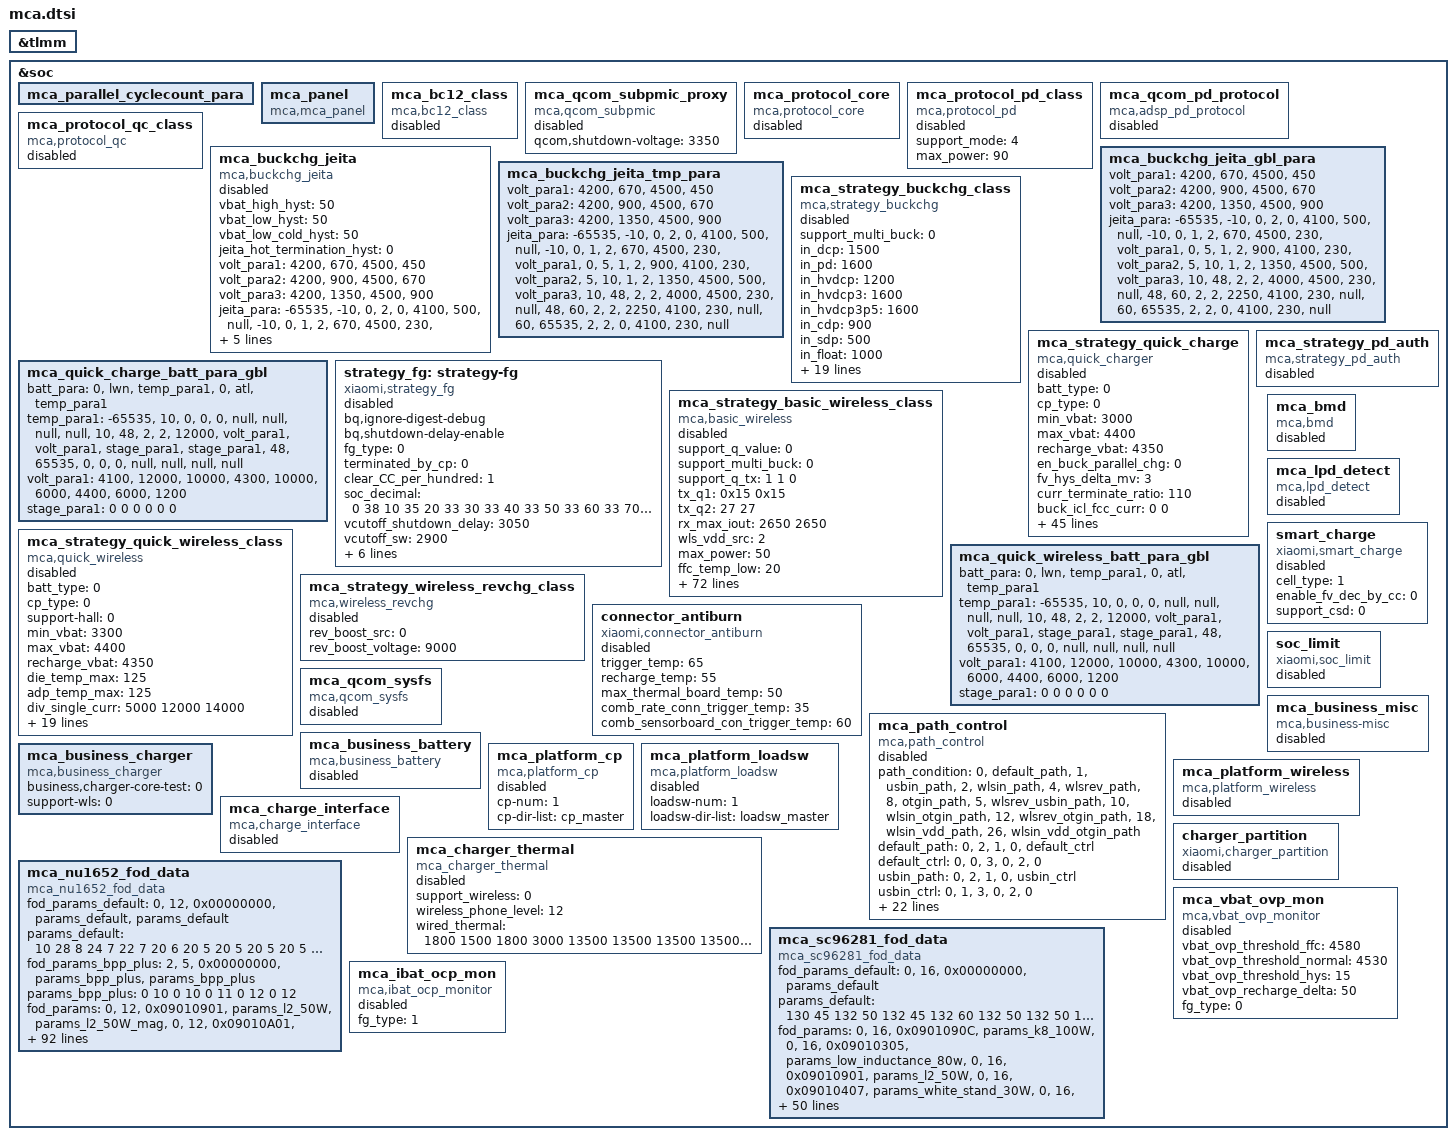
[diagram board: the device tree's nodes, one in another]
&tlmm {
};

&soc {
	mca_parallel_cyclecount_para: mca_parallel_cyclecount_para {
	};

	mca_panel: mca_panel {
		compatible = "mca,mca_panel";
		status = "ok";
	};

	mca_bc12_class: mca_bc12_class {
		compatible = "mca,bc12_class";
		status = "disabled";
	};

	mca_qcom_subpmic_proxy: mca_qcom_subpmic_proxy {
		compatible = "mca,qcom_subpmic";
		qcom,shutdown-voltage = <3350>;
		status = "disabled";
	};

	mca_protocol_core: mca_protocol_core {
		compatible = "mca,protocol_core";
		status = "disabled";
	};

	mca_protocol_pd_class: mca_protocol_pd_class {
		compatible = "mca,protocol_pd";
		status = "disabled";
		support_mode = <4>;
		max_power = <90>;
	};

	mca_qcom_pd_protocol: mca_qcom_pd_protocol {
		compatible = "mca,adsp_pd_protocol";
		status = "disabled";
	};

	mca_protocol_qc_class: mca_protocol_qc_class {
		compatible = "mca,protocol_qc";
		status = "disabled";
	};

	mca_buckchg_jeita: mca_buckchg_jeita {
		compatible = "mca,buckchg_jeita";
		vbat_high_hyst = <50>;
		vbat_low_hyst = <50>;
		vbat_low_cold_hyst = <50>;
		jeita_hot_termination_hyst = <0>;
		volt_para1 =
			"4200", "670",
			"4500", "450";
		volt_para2 =
			"4200", "900",
			"4500", "670";
		volt_para3 =
			"4200", "1350",
			"4500", "900";
		/* temp_low, temp_high, low_temp_hys, high_temp_hys, max_current, vterm, iterm volt_para_name */
		jeita_para =
			"-65535", "-10", "0", "2", "0", "4100", "500", "null",
			"-10", "0", "1", "2", "670", "4500", "230", "volt_para1",
			"0", "5", "1", "2", "900", "4100", "230", "volt_para2",
			"5", "10", "1", "2", "1350", "4500", "500", "volt_para3",
			"10", "48", "2", "2", "4000", "4500", "230", "null",
			"48", "60", "2", "2", "2250", "4100", "230", "null" ,
			"60", "65535", "2", "2", "0", "4100", "230", "null";

		status = "disabled";
	};

	mca_buckchg_jeita_gbl_para: mca_buckchg_jeita_gbl_para {
		volt_para1 =
			"4200", "670",
			"4500", "450";
		volt_para2 =
			"4200", "900",
			"4500", "670";
		volt_para3 =
			"4200", "1350",
			"4500", "900";
		/* temp_low, temp_high, low_temp_hys, high_temp_hys, max_current, vterm, iterm volt_para_name */
		jeita_para =
			"-65535", "-10", "0", "2", "0", "4100", "500", "null",
			"-10", "0", "1", "2", "670", "4500", "230", "volt_para1",
			"0", "5", "1", "2", "900", "4100", "230", "volt_para2",
			"5", "10", "1", "2", "1350", "4500", "500", "volt_para3",
			"10", "48", "2", "2", "4000", "4500", "230", "null",
			"48", "60", "2", "2", "2250", "4100", "230", "null" ,
			"60", "65535", "2", "2", "0", "4100", "230", "null";
	};

	mca_buckchg_jeita_tmp_para: mca_buckchg_jeita_tmp_para {
		volt_para1 =
			"4200", "670",
			"4500", "450";
		volt_para2 =
			"4200", "900",
			"4500", "670";
		volt_para3 =
			"4200", "1350",
			"4500", "900";
		/* temp_low, temp_high, low_temp_hys, high_temp_hys, max_current, vterm, iterm volt_para_name */
		jeita_para =
			"-65535", "-10", "0", "2", "0", "4100", "500", "null",
			"-10", "0", "1", "2", "670", "4500", "230", "volt_para1",
			"0", "5", "1", "2", "900", "4100", "230", "volt_para2",
			"5", "10", "1", "2", "1350", "4500", "500", "volt_para3",
			"10", "48", "2", "2", "4000", "4500", "230", "null",
			"48", "60", "2", "2", "2250", "4100", "230", "null" ,
			"60", "65535", "2", "2", "0", "4100", "230", "null";
	};

	mca_strategy_buckchg_class: mca_strategy_buckchg_class {
		compatible = "mca,strategy_buckchg";
		support_multi_buck = <0>;
		in_dcp = <1500>;
		in_pd = <1600>;
		in_hvdcp = <1200>;
		in_hvdcp3 = <1600>;
		in_hvdcp3p5 = <1600>;
		in_cdp = <900>;
		in_sdp = <500>;
		in_float = <1000>;
		chg_dcp = <2000>;
		chg_pd = <3000>;
		chg_hvdcp = <2600>;
		chg_hvdcp3 = <3600>;
		chg_hvdcp3p5 = <3600>;
		chg_cdp = <900>;
		chg_sdp = <500>;
		chg_float = <1000>;
		chg_batt_auth_failed = <2000>;
		ffc_temp_low = <20>;
		ffc_temp_high = <48>;
		pmic_fv_compensation = <0>;
		pmic_wls_fv_compensation = <0>;
		pmic_iterm_compensation = <30>;
		allow_start_ffc_batt_soc_thr = <95>;
		/* 0: No CP, 1: OVP before CP, 2: OVP before PMIC */
		vusb_ovp_location = <1>;

		//pps&pd_verify, other
		rev_req_vadp = <9000 9000>;
		rev_vadp_valid_h = <9200 9200>;
		rev_vadp_valid_l = <8400 8400>;

		status = "disabled";
	};


	mca_strategy_quick_charge: mca_strategy_quick_charge {
		compatible = "mca,quick_charger";
		status = "disabled";
		batt_type = <0>;
		cp_type = <0>;
		min_vbat = <3000>;
		max_vbat = <4400>;
		recharge_vbat = <4350>;
		en_buck_parallel_chg = <0>;
		fv_hys_delta_mv = <3>;
		curr_terminate_ratio = <110>;
		buck_icl_fcc_curr = <0 0>;
		die_temp_max = <125>;
		adp_temp_max = <125>;
		div_delta_volt = <300 300 500>;
		div_delta_ibat = <200 200 200>;
		div_single_curr = <5000 12000 14000>;
		div_max_curr = <5000 12000 14000>;
		multi_ibus_th = <2000 1500 600>;
		again_multi_ibus_th = <3500 3000 1000>;
		ibus_inc_hysteresis = <200 200 100>;
		ibus_dec_hysteresis = <200 200 100>;
		open_path_th = <800 600 400>;
		ibus_compensation = <0 0 0>;
		support_mode = <7>;
		max_power = <67000>;
		qc_normal_charge_fv = <4480>;
		qc3_max_vbus_limit = <9500>;
		qc3_max_ibus_limit = <2500>;
		qc3_ibat_max_limit = <5000>;
		qc3p5_max_vbus_limit = <10000>;
		qc3p5_max_ibus_limit = <2200>;
		qc3p5_ibat_max_limit = <4400>;
		qc_taper_fcc_thr = <2400>;
		qc_taper_soc_thr = <100>;
		pps_taper_fcc_thr = <2400>;
		qc3_taper_vol_hys = <25>;
		qc3p5_taper_vol_hys = <20>;
		pps_taper_vol_hys = <5>;
		quick_chg_fv_hys = <1>;
		mult_to_single_count = <0>;

		support_cp_vfc = <0>;
		vfc_iout_fsw_map =
			"6000", "720",
			"0", "300";
		support_curr_monitor = <0>;
		curr_monitor_time_s = <0>;
		cp_switch_pmic_th = <1500>;

		batt_para =
			"0", "lwn", "temp_para1",
			"0", "atl", "temp_para1";
		/* temp_low, temp_high, low_temp_hys, high_temp_hys, max_current, volt_para_name stage_para_name*/
		temp_para1 =
			"-65535", "10", "0", "0", "0", "null", "null", "null", "null",
			"10", "48", "2", "2", "12000", "volt_para1", "volt_para1", "stage_para1", "stage_para1",
			"48", "65535", "0", "0", "0", "null", "null", "null", "null";
		volt_para1 =
			"4100", "12000", "10000",
			"4300", "10000", "6000",
			"4400", "6000", "1200";
		stage_para1 = <0 0 0 0 0 0>;
		vstep_para =
			"1", "2000", "2",
			"2", "2000", "4",
			"4", "4000", "8",
			"4", "2000", "4",
			"4", "1000", "2";
	};

	mca_quick_charge_batt_para_gbl: mca_quick_charge_batt_para_gbl {
		batt_para =
			"0", "lwn", "temp_para1",
			"0", "atl", "temp_para1";
		/* temp_low, temp_high, low_temp_hys, high_temp_hys, max_current, volt_para_name stage_para_name*/
		temp_para1 =
			"-65535", "10", "0", "0", "0", "null", "null", "null", "null",
			"10", "48", "2", "2", "12000", "volt_para1", "volt_para1", "stage_para1", "stage_para1",
			"48", "65535", "0", "0", "0", "null", "null", "null", "null";
		volt_para1 =
			"4100", "12000", "10000",
			"4300", "10000", "6000",
			"4400", "6000", "1200";
		stage_para1 = <0 0 0 0 0 0>;
	};

	mca_strategy_pd_auth: mca_strategy_pd_auth {
		compatible = "mca,strategy_pd_auth";
		status = "disabled";
	};

	strategy_fg: strategy-fg {
		compatible = "xiaomi,strategy_fg";
		bq,ignore-digest-debug;
		bq,shutdown-delay-enable;
		fg_type = <0>;
		terminated_by_cp = <0>;
		clear_CC_per_hundred = <1>;
		soc_decimal = <
			0  38
			10 35
			20 33
			30 33
			40 33
			50 33
			60 33
			70 30
			80 25
			90 20
			95 10 >;
		vcutoff_shutdown_delay = <3050>;
		vcutoff_sw = <2900>;
		vcutoff_fw = <3050>;
		vterm_delta = <7>;
		support_fl4p0 = <0>;
		status = "disabled";
		extreme_cold_temp_compemsation =
			"100", "50", "50",
			"100", "150", "65",
			"350", "150", "80",
			"2147483647", "150", "100";
	};


	mca_strategy_basic_wireless_class: mca_strategy_basic_wireless_class {
		compatible = "mca,basic_wireless";
		support_q_value = <0>;
		support_multi_buck = <0>;
		/* low_inductance_tx_50W, low_inductance_tx_80W, params_magnet_30W */
		support_q_tx= <1 1 0>;
		tx_q1 = /bits/ 8 <0x15 0x15>;
		tx_q2 = <27 27>;
		rx_max_iout = <2650 2650>;
		wls_vdd_src = <2>;
		status = "disabled";
		max_power = <50>;
		ffc_temp_low = <20>;
		ffc_temp_high = <48>;
		support_mode = <4>;
		support-hall = <0>;
		phone_icl = <200>;
		phone_vol = <6000>;
		offstd_phone_icl = <100>;
		pmic_fv_compensation = <0>;
		soc_limit_fcc = <6000>;

		adapter_cmd_type_para =
			"0xF0", "adapter_cmd_type_f0",
			"0xF1", "adapter_cmd_type_f1",
			"0xF2", "adapter_cmd_type_f2",
			"0xF3", "adapter_cmd_type_f3",
			"0xF4", "adapter_cmd_type_f4",
			"0xF5", "adapter_cmd_type_f5";

		//icl, fcc
		adapter_cmd_type_f0 = <
			0 0	/* ADAPTER_NONE */
			0 0	/* ADAPTER_SDP */
			0 0	/* ADAPTER_CDP */
			0 0	/* ADAPTER_DCP */
			0 0	/* NULL */
			0 0	/* ADAPTER_QC2 */
			0 0	/* ADAPTER_QC3 */
			0 0	/* ADAPTER_PD */
			0 0	/* ADAPTER_AUTH_FAILED */
			0 0	/* ADAPTER_XIAOMI_QC3 */
			0 0	/* ADAPTER_XIAOMI_PD */
			0 0	/* ADAPTER_ZIMI_CAR_POWER */
			0 0	/* ADAPTER_XIAOMI_PD_40W */
			0 0	/* ADAPTER_VOICE_BOX */
			0 0	/* ADAPTER_XIAOMI_PD_50W */
			0 0	/* ADAPTER_XIAOMI_PD_60W */
			0 0	/* ADAPTER_XIAOMI_PD_100W */
		>;

		adapter_cmd_type_f1 = <
			0 0	/* ADAPTER_NONE */
			0 0	/* ADAPTER_SDP */
			0 0	/* ADAPTER_CDP */
			0 0	/* ADAPTER_DCP */
			0 0	/* NULL */
			0 0	/* ADAPTER_QC2 */
			0 0	/* ADAPTER_QC3 */
			0 0	/* ADAPTER_PD */
			0 0	/* ADAPTER_AUTH_FAILED */
			0 0	/* ADAPTER_XIAOMI_QC3 */
			0 0	/* ADAPTER_XIAOMI_PD */
			0 0	/* ADAPTER_ZIMI_CAR_POWER */
			0 4000	/* ADAPTER_XIAOMI_PD_40W */
			0 0	/* ADAPTER_VOICE_BOX */
			0 6000	/* ADAPTER_XIAOMI_PD_50W */
			0 6000	/* ADAPTER_XIAOMI_PD_60W */
			0 6000	/* ADAPTER_XIAOMI_PD_100W */
		>;

		adapter_cmd_type_f2 = <
			0 0	/* ADAPTER_NONE */
			0 0	/* ADAPTER_SDP */
			0 0	/* ADAPTER_CDP */
			0 0	/* ADAPTER_DCP */
			0 0	/* NULL */
			0 0	/* ADAPTER_QC2 */
			0 0	/* ADAPTER_QC3 */
			0 0	/* ADAPTER_PD */
			0 0	/* ADAPTER_AUTH_FAILED */
			0 0	/* ADAPTER_XIAOMI_QC3 */
			0 0	/* ADAPTER_XIAOMI_PD */
			0 0	/* ADAPTER_ZIMI_CAR_POWER */
			1300 3000	/* ADAPTER_XIAOMI_PD_40W */
			0 0	/* ADAPTER_VOICE_BOX */
			0 4000	/* ADAPTER_XIAOMI_PD_50W */
			0 4000	/* ADAPTER_XIAOMI_PD_60W */
			0 4000	/* ADAPTER_XIAOMI_PD_100W */
		>;

		adapter_cmd_type_f3 = <
			0 0	/* ADAPTER_NONE */
			0 0	/* ADAPTER_SDP */
			0 0	/* ADAPTER_CDP */
			0 0	/* ADAPTER_DCP */
			0 0	/* NULL */
			0 0	/* ADAPTER_QC2 */
			0 0	/* ADAPTER_QC3 */
			0 0	/* ADAPTER_PD */
			0 0	/* ADAPTER_AUTH_FAILED */
			0 0	/* ADAPTER_XIAOMI_QC3 */
			0 0	/* ADAPTER_XIAOMI_PD */
			0 0	/* ADAPTER_ZIMI_CAR_POWER */
			850 2000	/* ADAPTER_XIAOMI_PD_40W */
			0 0	/* ADAPTER_VOICE_BOX */
			850 2000	/* ADAPTER_XIAOMI_PD_50W */
			850 2000	/* ADAPTER_XIAOMI_PD_60W */
			850 2000	/* ADAPTER_XIAOMI_PD_100W */
		>;

		adapter_cmd_type_f4 = <
			0 0	/* ADAPTER_NONE */
			0 0	/* ADAPTER_SDP */
			0 0	/* ADAPTER_CDP */
			0 0	/* ADAPTER_DCP */
			0 0	/* NULL */
			0 0	/* ADAPTER_QC2 */
			0 0	/* ADAPTER_QC3 */
			0 0	/* ADAPTER_PD */
			0 0	/* ADAPTER_AUTH_FAILED */
			0 0	/* ADAPTER_XIAOMI_QC3 */
			0 0	/* ADAPTER_XIAOMI_PD */
			0 0	/* ADAPTER_ZIMI_CAR_POWER */
			400 1000	/* ADAPTER_XIAOMI_PD_40W */
			0 0	/* ADAPTER_VOICE_BOX */
			400 1000	/* ADAPTER_XIAOMI_PD_50W */
			400 1000	/* ADAPTER_XIAOMI_PD_60W */
			400 1000	/* ADAPTER_XIAOMI_PD_100W */
		>;

		adapter_cmd_type_f5 = <
			0 0	/* ADAPTER_NONE */
			0 0	/* ADAPTER_SDP */
			0 0	/* ADAPTER_CDP */
			0 0	/* ADAPTER_DCP */
			0 0	/* NULL */
			0 0	/* ADAPTER_QC2 */
			0 0	/* ADAPTER_QC3 */
			0 0	/* ADAPTER_PD */
			0 0	/* ADAPTER_AUTH_FAILED */
			0 0	/* ADAPTER_XIAOMI_QC3 */
			0 0	/* ADAPTER_XIAOMI_PD */
			0 0	/* ADAPTER_ZIMI_CAR_POWER */
			1300 2000	/* ADAPTER_XIAOMI_PD_40W */
			0 0	/* ADAPTER_VOICE_BOX */
			0 0	/* ADAPTER_XIAOMI_PD_50W */
			0 0	/* ADAPTER_XIAOMI_PD_60W */
			0 0	/* ADAPTER_XIAOMI_PD_100W */
		>;

		adapter_para =
			"0x09010A01", "adapter_para_91A1",	/* XIAOMI_TX_UUID_LOW_INDUCTANCE_50W */
			"0x09010305", "adapter_para_9135",	/* XIAOMI_TX_UUID_LOW_INDUCTANCE_80W */
			"0X09010904", "adapter_para_9194",	/* XIAOMI_TX_UUID_SAILBOAT_80W */
			"0x0901090C", "adapter_para_919C",	/* XIAOMI_TX_UUID_SAILBOAT_100W */
			"0x09010907", "adapter_para_9197",	/* XIAOMI_TX_UUID_REDMI_30W */
			"0x01010E01", "adapter_para_11E1",	/* XIAOMI_TX_UUID_TRAIN_20W */
			"0x01080205", "adapter_para_1825",	/* XIAOMI_TX_UUID_ZIMI_CAR_50W */
			"0x09080207", "adapter_para_9827",	/* XIAOMI_TX_UUID_ZIMI_CAR_30W */
			"0x06020801", "adapter_para_6281",	/* XIAOMI_TX_UUID_ZIMI_CAR_20W */
			"0x090C0201", "adapter_para_9C21",	/* XIAOMI_TX_UUID_KUKE_CAR_50W */
			"0x0C090908", "adapter_para_C998",	/* XIAOMI_TX_UUID_MULTI_COIL2_20W */
			"0x0C090906", "adapter_para_C996",	/* XIAOMI_TX_UUID_MULTI_COIL_20W */
			"0x09010506", "adapter_para_9156",	/* XIAOMI_TX_UUID_MOVING_PLATE_20W */
			"0x09080607", "adapter_para_9867",	/* XIAOMI_TX_UUID_MUSICAL_BOX_30W */
			"0x09018B07", "adapter_para_918B7";	/* XIAOMI_TX_UUID_MAGNET_30W */

		/* standard_tx, musical_box, plate_tx, car_mounted, train_tx, redmi_30w_tx,sailboat_tx ,
		low_inductance_50w_tx, low_inductance_80w_tx, support_fan, magnet_tx*/
		adapter_para_91A1 = "1", "0", "0", "0", "0", "0", "0", "1", "0", "1", "0";
		adapter_para_9135 = "0", "0", "0", "0", "0", "0", "0", "0", "1", "1", "0";
		adapter_para_9194 = "0", "0", "0", "0", "0", "0", "1", "0", "0", "1", "0";
		adapter_para_919C = "0", "0", "0", "0", "0", "0", "1", "0", "0", "1", "0";
		adapter_para_9197 = "0", "0", "0", "0", "0", "1", "0", "0", "0", "1", "0";
		adapter_para_11E1 = "0", "0", "0", "0", "1", "0", "0", "0", "0", "0", "0";
		adapter_para_1825 = "0", "0", "0", "1", "0", "0", "0", "0", "0", "0", "0";
		adapter_para_9827 = "0", "0", "0", "1", "0", "0", "0", "0", "0", "0", "0";
		adapter_para_6281 = "0", "0", "0", "1", "0", "0", "0", "0", "0", "0", "0";
		adapter_para_9C21 = "0", "0", "0", "1", "0", "0", "0", "0", "0", "0", "0";
		adapter_para_C998 = "0", "0", "1", "0", "0", "0", "0", "0", "0", "0", "0";
		adapter_para_C996 = "0", "0", "1", "0", "0", "0", "0", "0", "0", "0", "0";
		adapter_para_9156 = "0", "0", "1", "0", "0", "0", "0", "0", "0", "0", "0";
		adapter_para_9867 = "0", "1", "0", "0", "0", "0", "0", "0", "0", "0", "0";
		adapter_para_918B7 = "0", "0", "0", "0", "0", "0", "0", "0", "0", "0", "1";

	};

	mca_strategy_quick_wireless_class: mca_strategy_quick_wireless_class {
		compatible = "mca,quick_wireless";
		status = "disabled";
		batt_type = <0>;
		cp_type = <0>;
		support-hall = <0>;
		min_vbat = <3300>;
		max_vbat = <4400>;
		recharge_vbat = <4350>;
		die_temp_max = <125>;
		adp_temp_max = <125>;
		div_single_curr = <5000 12000 14000>;
		div_max_curr = <5000 12000 14000>;
		multi_ibus_th = <400 400 400>;
		ibus_inc_hysteresis = <100 100 100>;
		ibus_dec_hysteresis = <100 100 100>;
		support_mode = <4>;
		max_rx_vout_request = <19500>;
		support-cp-num-switch = <0>;
		sw_cv_taper_reduce_cv = <0>;
		batt_para =
			"0", "lwn", "temp_para1",
			"0", "atl", "temp_para1";
		/* temp_low, temp_high, low_temp_hys, high_temp_hys, max_current, volt_para_name stage_para_name*/
		temp_para1 =
			"-65535", "10", "0", "0", "0", "null", "null", "null", "null",
			"10", "48", "2", "2", "12000", "volt_para1", "volt_para1", "stage_para1", "stage_para1",
			"48", "65535", "0", "0", "0", "null", "null", "null", "null";
		volt_para1 =
			"4100", "12000", "10000",
			"4300", "10000", "6000",
			"4400", "6000", "1200";
		stage_para1 = <0 0 0 0 0 0>;
		vstep_para =
			"1", "2000", "2",
			"2", "2000", "4",
			"4", "4000", "10",
			"4", "2000", "5",
			"4", "1000", "2";
	};

	mca_quick_wireless_batt_para_gbl: mca_quick_wireless_batt_para_gbl {
		batt_para =
			"0", "lwn", "temp_para1",
			"0", "atl", "temp_para1";
		/* temp_low, temp_high, low_temp_hys, high_temp_hys, max_current, volt_para_name stage_para_name*/
		temp_para1 =
			"-65535", "10", "0", "0", "0", "null", "null", "null", "null",
			"10", "48", "2", "2", "12000", "volt_para1", "volt_para1", "stage_para1", "stage_para1",
			"48", "65535", "0", "0", "0", "null", "null", "null", "null";
		volt_para1 =
			"4100", "12000", "10000",
			"4300", "10000", "6000",
			"4400", "6000", "1200";
		stage_para1 = <0 0 0 0 0 0>;
	};


	mca_strategy_wireless_revchg_class: mca_strategy_wireless_revchg_class {
		compatible = "mca,wireless_revchg";
		status = "disabled";
		rev_boost_src = <0>;
		rev_boost_voltage = <9000>;
	};

	connector_antiburn: connector_antiburn {
		compatible = "xiaomi,connector_antiburn";
		status = "disabled";
		trigger_temp = <65>;
		recharge_temp = <55>;
		max_thermal_board_temp = <50>;
		comb_rate_conn_trigger_temp = <35>; //The connector trigger temperature combined with temperature increase rate.
		comb_sensorboard_con_trigger_temp = <60>; //The connector trigger temperature combined with temperature of thermal sensor board.
	};

	mca_bmd: mca_bmd {
		compatible = "mca,bmd";
		status = "disabled";
	};

	mca_path_control: mca_path_control {
		compatible = "mca,path_control";
		status = "disabled";
		path_condition =
			"0",  "default_path",	/* DEFAULT_CONDITION */
			"1",  "usbin_path",	/* USB_IN */
			"2",  "wlsin_path",	/* WIRELESS_IN */
			"4",  "wlsrev_path",	/* WIRELES_REV */
			"8",  "otgin_path",	/* OTG_IN */
			"5",  "wlsrev_usbin_path",	/* WIRELESS_REV_USB_IN */
			"10", "wlsin_otgin_path",	/* WIRELESS_IN_OTG_IN */
			"12", "wlsrev_otgin_path",	/* WIRELESS_REV_OTG_IN */
			"18", "wlsin_vdd_path",	/* WIRELESS_IN_VDD */
			"26", "wlsin_vdd_otgin_path";	/* WIRELESS_IN_VDD_IN_OTG_IN */
		/* src1, xxx_src, src2, yyy_src control_para */
		default_path =
			"0", "2", "1", "0", "default_ctrl";
		default_ctrl =
			"0", "0",
			"3", "0",
			"2", "0";
		usbin_path =
			"0", "2", "1", "0", "usbin_ctrl";
		/* control_gate_role, enable */
		usbin_ctrl =
			"0", "1",
			"3", "0",
			"2", "0";
		wlsin_path =
			"0", "2", "1", "0", "wlsin_ctrl";
		wlsin_ctrl =
			"0", "0",
			"3", "0",
			"2", "0";
		wlsrev_path =
			"0", "2", "1", "0", "wlsrev_ctrl";
		wlsrev_ctrl =
			"0", "0",
			"3", "0",
			"2", "0";
		otgin_path =
			"0", "2", "1", "0", "otgin_ctrl";
		otgin_ctrl =
			"0", "0",
			"3", "1",
			"2", "1";
		wlsrev_usbin_path =
			"0", "2", "1", "0", "wlsrev_usbin_ctrl";
		wlsrev_usbin_ctrl =
			"0", "1",
			"3", "0",
			"2", "0";
		wlsin_otgin_path =
			"0", "2", "1", "0", "wlsin_otgin_ctrl";
		wlsin_otgin_ctrl =
			"0", "0",
			"3", "1",
			"2", "1";
		wlsrev_otgin_path =
			"0", "2", "1", "0", "wlsrev_otgin_ctrl";
		wlsrev_otgin_ctrl =
			"0", "0",
			"3", "1",
			"2", "1";
		wlsin_vdd_path =
			"0", "2", "1", "0", "wlsin_vdd_ctrl";
		wlsin_vdd_ctrl =
			"0", "0",
			"3", "1",
			"2", "0";
		wlsin_vdd_otgin_path =
			"0", "2", "1", "0", "wlsin_vdd_otgin_ctrl";
		wlsin_vdd_otgin_ctrl =
			"0", "0",
			"3", "1",
			"2", "1";

		/* gate_type, control_scheme, process_way */
		/* gate_type: 0:ovpgate, 1:wpcgate, 2:ext_bst_gate,
						3:wireless_vdd_gate, 4:haptics_bst_gate */
		/* control_scheme: 0:GPIO 1:PMIC_REGISTER 2:CP_CHIP */
		control_scheme =
			"0", "2", "ovpgate,cp_chip_role",
			"1", "2", "null",
			"2", "0", "null",
			"3", "0", "null",
			"4", "0", "null";
		/* chip_project, chip_role */
		ovpgate,cp_chip_role = <0>;
	};

	mca_lpd_detect: mca_lpd_detect {
		compatible = "mca,lpd_detect";
		status = "disabled";
	};

	smart_charge: smart_charge {
		compatible = "xiaomi,smart_charge";
		cell_type = <1>;
		status = "disabled";
		enable_fv_dec_by_cc = <0>;
		support_csd = <0>;
	};

	soc_limit: soc_limit {
		compatible = "xiaomi,soc_limit";
		status = "disabled";
	};

	mca_qcom_sysfs: mca_qcom_sysfs {
		compatible = "mca,qcom_sysfs";
		status = "disabled";
	};


	mca_business_misc: mca_business_misc {
		compatible = "mca,business-misc";
		status = "disabled";
	};

	mca_business_battery: mca_business_battery {
		compatible = "mca,business_battery";
		status = "disabled";
	};

	mca_business_charger: mca_business_charger {
		compatible = "mca,business_charger";

		/* charger_core */
		business,charger-core-test = <0>;
		support-wls = <0>; /*1:support wls; 0: no wls*/
		status = "ok";
	};

	mca_platform_cp: mca_platform_cp {
		compatible = "mca,platform_cp";
		status = "disabled";
		cp-num = <1>;
		cp-dir-list = "cp_master";
	};

	mca_platform_loadsw: mca_platform_loadsw {
		compatible = "mca,platform_loadsw";
		status = "disabled";
		loadsw-num = <1>;
		loadsw-dir-list = "loadsw_master";
	};

	mca_platform_wireless: mca_platform_wireless {
		compatible = "mca,platform_wireless";
		status = "disabled";
	};

	mca_charge_interface: mca_charge_interface {
		compatible = "mca,charge_interface";
		status = "disabled";
	};

	mca_charger_thermal: mca_charger_thermal {
		compatible = "mca_charger_thermal";
		support_wireless = <0>;
		wireless_phone_level = <12>;
		/* 5v_in 9v_in 5v_ichg 9v_ichg div1_single div1_multi div2_single div2_multi div4_single div4_multi*/
		wired_thermal = <
		1800 1500 1800 3000 13500 13500 13500 13500 13500 13500 /* level 1 */
		1800 1500 1800 3000 11000 11000 11000 11000 11000 11000 /* level 2 */
		1800 1500 1800 3000 9000  9000  9000  9000  9000  9000  /* level 3 */
		1800 1500 1800 3000 8000  8000  8000  8000  8000  8000  /* level 4 */
		1800 1500 1800 3000 7000  7000  7000  7000  7000  7000  /* level 5 */
		1800 1400 1800 2800 6000  6000  6000  6000  6000  6000  /* level 6 */
		1800 1300 1800 2600 5000  5000  5000  5000  5000  5000  /* level 7 */
		1800 1150 1800 2310 4000  4000  4000  4000  4000  4000  /* level 8 */
		1700 1100 1700 2200 3500  3500  3500  3500  3500  3500  /* level 9 */
		1600 1000 1600 2000 3000  3000  3000  3000  3000  3000  /* level 10 */
		1400 900  1400 1800 2500  2500  2500  2500  2500  2500  /* level 11 */
		1200 850  1200 1600 2000  2000  2000  2000  2000  2000  /* level 12 */
		1100 750  1100 1500 1500  1500  1500  1500  1500  1500  /* level 13 */
		1100 650  1100 1300 1000  1000  1000  1000  1000  1000  /* level 14 */
		1000 500  1000 1000 500   500   500   500   500   500   /* level 15 */
		>;
		status = "disabled";
	};

	mca_nu1652_fod_data: mca_nu1652_fod_data {
		compatible = "mca_nu1652_fod_data";

		/* type, length, uuid, params_no_mag, params_mag */
		fod_params_default =
			"0", "12", "0x00000000", "params_default", "params_default";
		params_default = /bits/ 8 <
			10 28
			8  24
			7  22
			7  20
			6  20
			5  20
			5  20
			5  20
			5  20
			5  20
			4  20
			4  20
		>;

		/* type, length, uuid, params_no_mag, params_mag */
		fod_params_bpp_plus =
			"2", "5",  "0x00000000", "params_bpp_plus", "params_bpp_plus";
		params_bpp_plus = /bits/ 8 <
			0 10
			0 10
			0 11
			0 12
			0 12
		>;

		/* type, length, uuid, params_no_mag, params_mag */
		fod_params =
			"0", "12", "0x09010901", "params_l2_50W", "params_l2_50W_mag",
			"0", "12", "0x09010A01", "params_m2_50W", "params_m2_50W_mag",
			"0", "12", "0x09010904", "params_k1_80W", "params_k1_80W_mag",
			"0", "12", "0x0901090C", "params_k8_100W", "params_k8_100W_mag",
			"0", "12", "0x0901010B", "params_j1s_55W", "params_j1s_55W_mag",
			"0", "12", "0x09010407", "params_white_stand_30W", "params_white_stand_30W_mag",
			"0", "12", "0x09080607", "params_bluetooth_30W", "params_bluetooth_30W",
			"0", "12", "0x09010506", "params_moving_20W", "params_moving_20W_mag",
			"0", "12", "0x09080108", "params_zimi_20W", "params_zimi_20W_mag",
			"0", "12", "0x06010101", "params_white_20W", "params_white_20W",
			"0", "12", "0x07030801", "params_power_bank_30W", "params_power_bank_30W",
			"0", "12", "0x06020801", "params_zimi_car_20W", "params_zimi_car_20W_mag",
			"0", "12", "0x0C090906", "params_multcoil_20W", "params_multcoil_20W_mag",
			"0", "12", "0x0C090908", "params_multcoil_20W", "params_multcoil_20W_mag",
			"0", "12", "0x09010907", "params_redmi_disc_30W", "params_redmi_disc_30W_mag",
			"0", "12", "0x09010305", "params_n1_80W", "params_n1_80W_mag",
			"0", "12", "0x09010A07", "params_double_coil_30W", "params_double_coil_30W_mag",
			"0", "12", "0x09018B07", "params_magnet_30W", "params_magnet_30W_mag";
		/* gain, offset */
		params_l2_50W = /bits/ 8 <
			12 28
			12 26
			12 22
			10 16
			10 10
			8  8
			7  6
			6  4
			5  2
			4  2
			4  2
			4  2
		>;
		params_l2_50W_mag = /bits/ 8 <
			10 18
			10 16
			10 12
			10 10
			8  8
			6  6
			4  6
			4  6
			4  4
			3  2
			3  0
			3  0
		>;

		params_m2_50W = /bits/ 8 <
			12 20
			12 18
			12 16
			10 12
			8  6
			6  6
			4  4
			4  4
			3  4
			3  4
			3  2
			3  2
		>;
		params_m2_50W_mag = /bits/ 8 <
			12 20
			12 18
			12 16
			10 12
			8  6
			6  6
			4  4
			4  4
			3  4
			3  4
			3  2
			3  2
		>;

		params_k1_80W = /bits/ 8 <
			14 28
			14 18
			14 16
			12 12
			11 10
			10 10
			9  8
			8  8
			8  2
			7  0
			7  0
			7  0
		>;
		params_k1_80W_mag = /bits/ 8 <
			14 28
			14 18
			14 16
			12 12
			11 10
			10 10
			9  8
			8  8
			8  2
			7  0
			7  0
			7  0
		>;

		params_k8_100W = /bits/ 8 <
			14 28
			14 18
			14 16
			12 12
			12 12
			10 10
			9  10
			8  8
			7  4
			7  2
			7  2
			7  2
		>;
		params_k8_100W_mag = /bits/ 8 <
			14 28
			14 18
			14 16
			12 12
			12 12
			10 10
			9  10
			8  8
			7  4
			7  2
			7  2
			7  2
		>;

		params_j1s_55W = /bits/ 8 <
			12 28
			12 26
			12 22
			10 16
			10 10
			8  8
			7  6
			6  4
			5  2
			4  2
			4  2
			4  2
		>;
		params_j1s_55W_mag = /bits/ 8 <
			10 20
			10 18
			10 12
			10 10
			8  8
			6  4
			4  4
			4  4
			4  2
			3  0
			3  0
			3  0
		>;


		params_magnet_30W = /bits/ 8 <
			16 15
			16 15
			16 15
			16 15
			16 15
			16 15
			16 15
			16 15
			16 15
			16 15
			16 15
			16 15
		>;
		params_magnet_30W_mag = /bits/ 8 <
			14 15
			14 12
			14 12
			13 12
			13 12
			13 12
			13 12
			13 12
			13 12
			13 12
			13 12
			13 12
		>;

		params_white_stand_30W = /bits/ 8 <
			12 26
			12 18
			12 14
			12 10
			10 6
			9  4
			9  2
			9  2
			9  2
			9  2
			9  2
			9  2
		>;
		params_white_stand_30W_mag = /bits/ 8 <
			12 26
			12 18
			12 14
			12 10
			10 6
			9  4
			9  2
			9  2
			9  2
			9  2
			9  2
			9  2
		>;

		params_bluetooth_30W = /bits/ 8 <
			12 18
			12 18
			12 17
			10 15
			10 15
			8  13
			8  13
			8  13
			8  13
			8  13
			8  13
			8  13
		>;

		params_moving_20W = /bits/ 8 <
			10 16
			10 14
			10 10
			8  8
			8  8
			8  8
			8  8
			8  8
			8  8
			8  8
			8  8
			8  8
		>;
		params_moving_20W_mag = /bits/ 8 <
			10 16
			10 14
			10 10
			8  8
			8  8
			8  8
			8  8
			8  8
			8  8
			8  8
			8  8
			8  8
		>;

		params_zimi_20W = /bits/ 8 <
			12 20
			13 20
			13 20
			13 18
			12 12
			10 10
			10 10
			10 10
			10 10
			10 10
			10 10
			10 10
		>;
		params_zimi_20W_mag = /bits/ 8 <
			10 20
			10 18
			10 18
			10 16
			10 16
			10 16
			10 16
			10 10
			10 10
			10 10
			10 10
			10 10
		>;

		params_white_20W = /bits/ 8 <
			10 24
			10 18
			10 18
			10 15
			10 15
			10 10
			10 10
			10 10
			10 10
			10 10
			10 10
			10 10
		>;

		params_power_bank_30W = /bits/ 8 <
			2  7
			2  7
			3  7
			6  11
			7  12
			8  13
			8  13
			8  13
			8  13
			8  13
			8  13
			8  13
		>;

		params_zimi_car_20W = /bits/ 8 <
			5  12
			5  12
			5  12
			5  10
			5  10
			5  8
			5  8
			5  8
			5  8
			5  8
			5  8
			5  8
		>;

		params_zimi_car_20W_mag = /bits/ 8 <
			5  12
			5  12
			5  12
			5  10
			5  10
			5  8
			5  8
			5  8
			5  8
			5  8
			5  8
			5  8
		>;

		params_multcoil_20W = /bits/ 8 <
			10  20
			10  18
			10  16
			10  16
			10  16
			10  16
			10  16
			10  16
			10  16
			10  16
			10  16
			10  16
		>;
		params_multcoil_20W_mag = /bits/ 8 <
			10  20
			10  18
			10  16
			10  16
			10  16
			10  16
			10  16
			10  16
			10  16
			10  16
			10  16
			10  16
		>;

		params_redmi_disc_30W = /bits/ 8 <
			10 22
			10 15
			10 10
			10 6
			9  6
			9  4
			8  2
			8  2
			8  2
			8  2
			8  2
			8  2
		>;
		params_redmi_disc_30W_mag = /bits/ 8 <
			10 22
			10 15
			10 10
			10 6
			9  6
			9  4
			8  2
			8  2
			8  2
			8  2
			8  2
			8  2
		>;

		params_n1_80W = /bits/ 8 <
			10 22
			10 15
			10 10
			10 6
			9  6
			9  4
			8  2
			8  2
			8  2
			8  2
			8  2
			8  2
		>;
		params_n1_80W_mag = /bits/ 8 <
			10 22
			10 15
			10 10
			10 6
			9  6
			9  4
			8  2
			8  2
			8  2
			8  2
			8  2
			8  2
		>;

		params_double_coil_30W = /bits/ 8 <
			10 22
			10 15
			10 10
			10 6
			9  6
			9  4
			8  2
			8  2
			8  2
			8  2
			8  2
			8  2
		>;
		params_double_coil_30W_mag = /bits/ 8 <
			10 22
			10 15
			10 10
			10 6
			9  6
			9  4
			8  2
			8  2
			8  2
			8  2
			8  2
			8  2
		>;
	};

mca_sc96281_fod_data: mca_sc96281_fod_data {
		compatible = "mca_sc96281_fod_data";

		fod_params_default =
			"0", "16", "0x00000000", "params_default";
		params_default = /bits/ 8 <
			130  45
			132  50
			132  45
			132  60
			132  50
			132  50
			130  99
			130  99
			130  99
			130  99
			130  99
			130  99
			130  99
			130  99
			130  99
			130  99
		>;

		/* type, length, uuid, params */
		fod_params =
			"0", "16", "0x0901090C", "params_k8_100W",
			"0", "16", "0x09010305", "params_low_inductance_80w",
			"0", "16", "0x09010901", "params_l2_50W",
			"0", "16", "0x09010407", "params_white_stand_30W",
			"0", "16", "0x09010904", "params_k1_80W",
			"0", "16", "0x09010A01", "params_m2_50W",
			"0", "16", "0x0901010B", "params_j1s_55W",
			"0", "16", "0x01080205", "params_zimi_car_50W",
			"0", "16", "0x09080207", "params_zimi_car_30W",
			"0", "16", "0x09010907", "params_redmi_disc_30W",
			"0", "16", "0x09080108", "params_zimi_20W",
			"0", "16", "0x09010506", "params_moving_20W",
			"0", "16", "0x09010A07", "params_double_coil_30W",
			"0", "16", "0x06010101", "params_white_20W",
			"0", "16", "0x0C090908", "params_multcoil_20W",
			"0", "16", "0x06020801", "params_zimi_car_20W",
			"0", "16", "0x09080607", "params_bluetooth_30W",
			"0", "16", "0x07030801", "params_power_bank_30W";
		/* gain, offset */
		params_k8_100W = /bits/ 8 <
			81   59
			81   66
			185  219
			197  181
			84   100
			178  185
			150  226
			177  155
			128  32
			126  37
			129  24
			108  100
			142  229
			159  155
			147  209
			156  160
		>;

		params_low_inductance_80w = /bits/ 8 <
			110  16
			115  20
			120  19
			120  18
			124  18
			124  30
			124  17
			124  17
			124  20
			125  20
			124  4
			124  10
			125  10
			125  10
			125  10
			125  10
		>;

		params_l2_50W = /bits/ 8 <
			70   55
			85   79
			104  70
			101  75
			103  80
			110  70
			110  67
			108  80
			103  89
			111  80
			113  67
			110  90
			120  45
			120  39
			120  39
			124  20
		>;

		params_white_stand_30W = /bits/ 8 <
			118  50
			121  48
			121  49
			125  46
			126  49
			126  40
			126  42
			126  41
			126  39
			126  38
			126  36
			126  36
			126  36
			126  36
			126  36
			125  20
		>;

		params_k1_80W = /bits/ 8 <
			70   70
			92   70
			100  67
			100  75
			110  70
			115  65
			117  60
			117  65
			117  65
			117  70
			118  70
			120  65
			123  65
			127  50
			128  42
			128  35
		>;

		params_m2_50W = /bits/ 8 <
			128  60
			126  45
			125  48
			125  48
			125  40
			125  40
			128  40
			128  46
			128  48
			128  45
			128  40
			128  40
			129  40
			129  50
			129  60
			129  70
		>;

		params_j1s_55W = /bits/ 8 <
			39   99
			123  63
			172  247
			148  24
			141  33
			159  245
			136  33
			109  100
			111  100
			175  165
			114  100
			141  4
			124  66
			116  100
			126  48
			112  100
		>;

		params_zimi_car_50W = /bits/ 8 <
			120  25
			120  10
			120  15
			120  20
			102  19
			111  25
			123  25
			123  30
			129  15
			124  20
			126  20
			126  20
			112  40
			112  40
			112  40
			112  40
		>;

		params_zimi_car_30W = /bits/ 8 <
			128  40
			127  34
			127  34
			127  34
			126  34
			125  38
			125  38
			124  41
			124  43
			123  40
			126  36
			126  36
			128  40
			128  40
			128  40
			128  40
		>;

		params_redmi_disc_30W = /bits/ 8 <
			125  30
			118  35
			120  30
			120  30
			120  44
			121  40
			121  40
			121  40
			121  40
			122  40
			122  40
			124  32
			126  42
			128  42
			127  42
			126  42
		>;

		params_zimi_20W = /bits/ 8 <
			120  30
			124  45
			127  40
			127  40
			127  40
			127  40
			128  40
			127  40
			128  40
			128  40
			128  40
			128  40
			128  40
			128  40
			128  40
			128  40
		>;

		params_moving_20W = /bits/ 8 <
			122  30
			121  32
			123  22
			126  21
			126  27
			126  27
			122  24
			122  24
			122  24
			122  24
			122  24
			122  24
			122  24
			122  24
			122  24
			122  24
		>;

		params_double_coil_30W = /bits/ 8 <
			128  40
			127  34
			127  34
			127  34
			126  34
			125  38
			125  38
			124  41
			124  43
			123  40
			126  36
			126  36
			128  40
			128  40
			128  40
			128  40
		>;

		params_power_bank_30W = /bits/ 8 <
			120  25
			120  10
			120  15
			120  24
			102  29
			111  35
			123  35
			123  40
			129  25
			124  40
			126  40
			126  40
			112  40
			112  40
			112  40
			112  40
		>;

		params_white_20W = /bits/ 8 <
			128  10
			128  10
			128  10
			128  10
			128  31
			128  31
			128  34
			128  34
			128  35
			128  35
			128  35
			128  35
			128  40
			128  40
			128  40
			128  40
		>;

		params_multcoil_20W = /bits/ 8 <
			120  25
			120  10
			120  15
			120  20
			102  19
			111  25
			123  25
			123  30
			129  15
			124  20
			126  20
			126  20
			112  40
			112  40
			112  40
			112  40
		>;

		params_zimi_car_20W = /bits/ 8 <
			120  25
			120  10
			120  15
			120  20
			102  19
			111  25
			123  25
			123  30
			129  15
			124  20
			126  20
			126  20
			112  40
			112  40
			112  40
			112  40
		>;

		params_bluetooth_30W = /bits/ 8 <
			128  32
			138  40
			128  38
			125  37
			125  33
			126  40
			144  2
			129  40
			153  215
			149  222
			149  215
			127  40
			128  60
			128  60
			128  60
			128  60
		>;
	};

	charger_partition: charger_partition {
		compatible = "xiaomi,charger_partition";
		status = "disabled";
	};

	mca_vbat_ovp_mon: mca_vbat_ovp_mon {
		compatible = "mca,vbat_ovp_monitor";
		vbat_ovp_threshold_ffc = <4580>;
		vbat_ovp_threshold_normal = <4530>;
		vbat_ovp_threshold_hys = <15>;
		vbat_ovp_recharge_delta = <50>;
		fg_type = <0>;
		status = "disabled";
	};

	mca_ibat_ocp_mon: mca_ibat_ocp_mon {
		compatible = "mca,ibat_ocp_monitor";
		fg_type = <1>;
		status = "disabled";
	};
};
